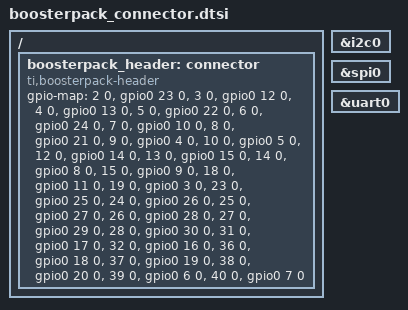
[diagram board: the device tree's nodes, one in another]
/*
 * Copyright (c) 2019 Brett Witherspoon
 *
 * SPDX-License-Identifier: Apache-2.0
 */

/ {
	boosterpack_header: connector {
		compatible = "ti,boosterpack-header";
		#gpio-cells = <2>;
		gpio-map = <2 0 &gpio0 23 0>,
			   <3 0 &gpio0 12 0>,
			   <4 0 &gpio0 13 0>,
			   <5 0 &gpio0 22 0>,
			   <6 0 &gpio0 24 0>,
			   <7 0 &gpio0 10 0>,
			   <8 0 &gpio0 21 0>,
			   <9 0 &gpio0 4 0>,
			   <10 0 &gpio0 5 0>,
			   <12 0 &gpio0 14 0>,
			   <13 0 &gpio0 15 0>,
			   <14 0 &gpio0 8 0>,
			   <15 0 &gpio0 9 0>,
			   <18 0 &gpio0 11 0>,
			   <19 0 &gpio0 3 0>,
			   <23 0 &gpio0 25 0>,
			   <24 0 &gpio0 26 0>,
			   <25 0 &gpio0 27 0>,
			   <26 0 &gpio0 28 0>,
			   <27 0 &gpio0 29 0>,
			   <28 0 &gpio0 30 0>,
			   <31 0 &gpio0 17 0>,
			   <32 0 &gpio0 16 0>,
			   <36 0 &gpio0 18 0>,
			   <37 0 &gpio0 19 0>,
			   <38 0 &gpio0 20 0>,
			   <39 0 &gpio0 6 0>,
			   <40 0 &gpio0 7 0>;
	};
};

boosterpack_i2c: &i2c0 {};

boosterpack_spi: &spi0 {};

boosterpack_serial: &uart0 {};
